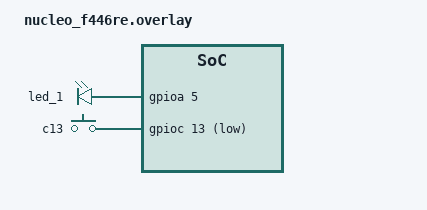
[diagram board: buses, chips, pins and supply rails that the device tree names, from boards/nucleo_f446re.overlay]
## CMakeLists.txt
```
cmake_minimum_required(VERSION 3.20.0)
set(ZEPHYR_EXTRA_MODULES "${CMAKE_SOURCE_DIR}/../../my_modules/button")
find_package(Zephyr REQUIRED HINTS $ENV{ZEPHYR_BASE})
project(custom_driver)
target_sources(app PRIVATE src/main.c)
```

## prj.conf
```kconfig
CONFIG_CUSTOM_BUTTON=y
CONFIG_LOG=y
CONFIG_LOG_DEFAULT_LEVEL=4
CONFIG_USB_DEVICE_STACK=y
CONFIG_USB_CDC_ACM=y
CONFIG_PRINTK=y
```

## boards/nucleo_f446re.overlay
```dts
/ {
    aliases {
        my-button-1 = &custom_button_1;
	my-led=&led_1;
    };

    custom-buttons {
        

        custom_button_1: the_button {
	    compatible = "custom,button";
            pin = <&c13>;
        };
    };
    leds: leds{
      compatible="gpio-leds";
      led_1: green_led{
        gpios=<&gpioa 5 GPIO_ACTIVE_HIGH>;
      };
    };

    

    gpio-keys {
        compatible = "gpio-keys";
        polling-mode;
        debounce-interval-ms = <50>;

        c13: custom_key {
            gpios = <&gpioc 13 GPIO_ACTIVE_LOW>;
        };
    };
};
```

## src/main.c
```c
#include <zephyr/kernel.h>
#include <stdio.h>
#include "button.h"
#include <zephyr/drivers/gpio.h>
static const struct device *holy_btn=DEVICE_DT_GET(DT_ALIAS(my_button_1));
static const uint32_t time=1000;
static const struct gpio_dt_spec led=GPIO_DT_SPEC_GET(DT_ALIAS(my_led),gpios);
int main(){
  int res;
  if(!device_is_ready(holy_btn)){
     printk("Button has not been configures properly\n");
     return 0;
  }
  uint8_t led_status;
  uint8_t status;
  int ret;
  ret=gpio_pin_configure_dt(&led,GPIO_OUTPUT_ACTIVE);
  const struct button_api *btn_api=(const struct button_api*)holy_btn->api; 
  while(1){
    res=btn_api->get(holy_btn,&status);
    if(res<0){
      printk("THe button has not been configured properly\n");
      continue;
    }
    printk("%u\n",status);
    gpio_pin_set_dt(&led,status);
    printk("The green led is in state : %u\n",status);
    k_msleep(time);
    
  }

  return 0;
}
```
